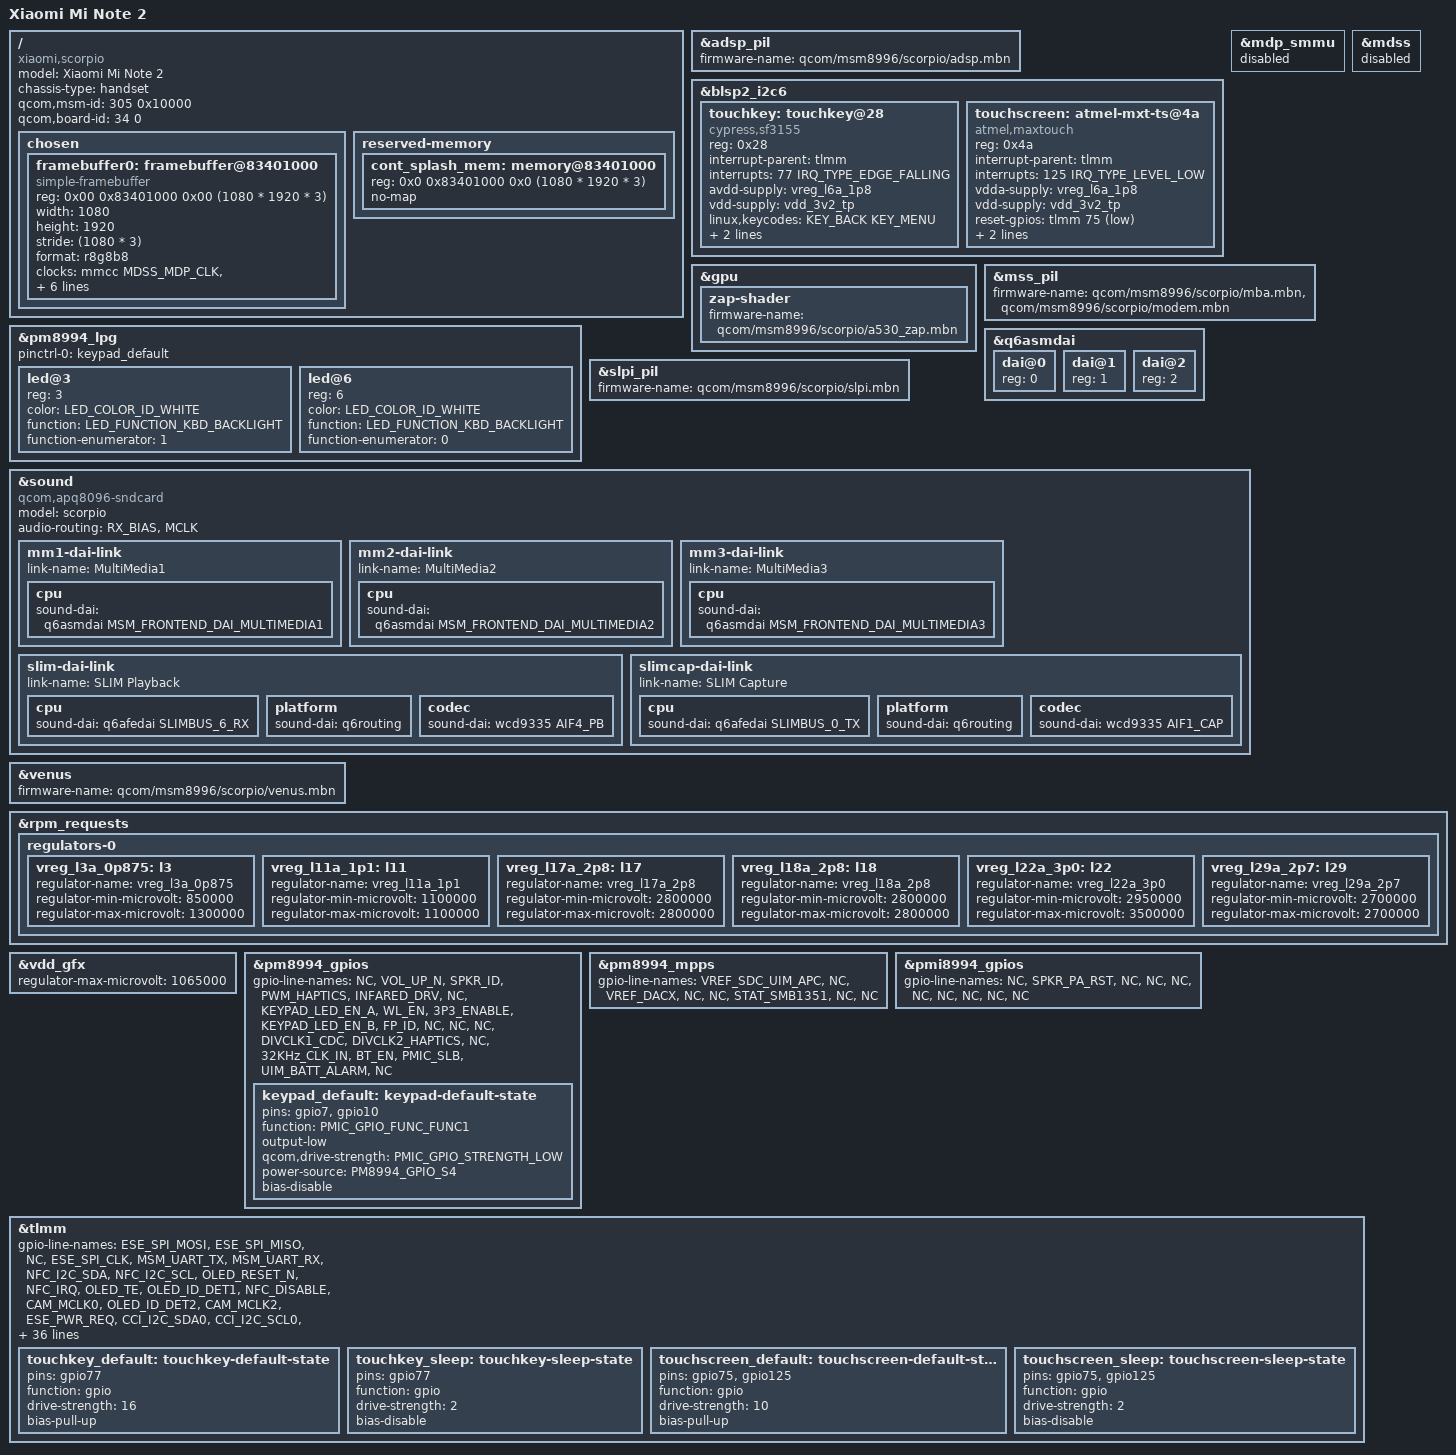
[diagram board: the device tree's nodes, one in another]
/dts-v1/;
#include "msm8996pro.dtsi"
#include "msm8996-xiaomi-common.dtsi"
#include "pmi8996.dtsi"
#include <dt-bindings/sound/qcom,q6afe.h>
#include <dt-bindings/sound/qcom,q6asm.h>
#include <dt-bindings/sound/qcom,wcd9335.h>
/ {
	model = "Xiaomi Mi Note 2";
	compatible = "xiaomi,scorpio", "qcom,msm8996pro", "qcom,msm8996";
	chassis-type = "handset";
	qcom,msm-id = <305 0x10000>;
	qcom,board-id = <34 0>;
	chosen {
		#address-cells = <2>;
		#size-cells = <2>;
		ranges;
		framebuffer0: framebuffer@83401000 {
			compatible = "simple-framebuffer";
			reg = <0x00 0x83401000 0x00 (1080 * 1920 * 3)>;
			width = <1080>;
			height = <1920>;
			stride = <(1080 * 3)>;
			format = "r8g8b8";
			clocks = <&mmcc MDSS_MDP_CLK>,
				 <&mmcc MMSS_MMAGIC_AHB_CLK>,
				 <&mmcc MDSS_AHB_CLK>,
				 <&mmcc MDSS_AXI_CLK>,
				 <&mmcc MMSS_MISC_AHB_CLK>,
				 <&mmcc MDSS_BYTE0_CLK>,
				 <&mmcc MDSS_PCLK0_CLK>,
				 <&mmcc MDSS_ESC0_CLK>,
				 <&mmcc SMMU_MDP_AHB_CLK>,
				 <&mmcc SMMU_MDP_AXI_CLK>;
			power-domains = <&mmcc MDSS_GDSC>;
		};
	};
	reserved-memory {
		cont_splash_mem: memory@83401000 {
			reg = <0x0 0x83401000 0x0 (1080 * 1920 * 3)>;
			no-map;
		};
	};
};
&adsp_pil {
	firmware-name = "qcom/msm8996/scorpio/adsp.mbn";
};
&blsp2_i2c6 {
	touchkey: touchkey@28 {
		compatible = "cypress,sf3155";
		reg = <0x28>;
		interrupt-parent = <&tlmm>;
		interrupts = <77 IRQ_TYPE_EDGE_FALLING>;
		avdd-supply = <&vreg_l6a_1p8>;
		vdd-supply = <&vdd_3v2_tp>;
		linux,keycodes = <KEY_BACK KEY_MENU>;
		pinctrl-names = "default", "sleep";
		pinctrl-0 = <&touchkey_default>;
		pinctrl-1 = <&touchkey_sleep>;
	};
	touchscreen: atmel-mxt-ts@4a {
		compatible = "atmel,maxtouch";
		reg = <0x4a>;
		interrupt-parent = <&tlmm>;
		interrupts = <125 IRQ_TYPE_LEVEL_LOW>;
		vdda-supply = <&vreg_l6a_1p8>;
		vdd-supply = <&vdd_3v2_tp>;
		reset-gpios = <&tlmm 75 GPIO_ACTIVE_LOW>;
		pinctrl-names = "default", "sleep";
		pinctrl-0 = <&touchscreen_default>;
		pinctrl-1 = <&touchscreen_sleep>;
	};
};
&gpu {
	zap-shader {
		firmware-name = "qcom/msm8996/scorpio/a530_zap.mbn";
	};
};
&mdp_smmu {
	status = "disabled";
};
&mdss {
	status = "disabled";
};
&mss_pil {
	firmware-name = "qcom/msm8996/scorpio/mba.mbn",
			"qcom/msm8996/scorpio/modem.mbn";
};
&pm8994_lpg {
	pinctrl-names = "default";
	pinctrl-0 = <&keypad_default>;
	led@3 {
		reg = <3>;
		color = <LED_COLOR_ID_WHITE>;
		function = LED_FUNCTION_KBD_BACKLIGHT;
		function-enumerator = <1>;
	};
	led@6 {
		reg = <6>;
		color = <LED_COLOR_ID_WHITE>;
		function = LED_FUNCTION_KBD_BACKLIGHT;
		function-enumerator = <0>;
	};
};
&q6asmdai {
	dai@0 {
		reg = <0>;
	};
	dai@1 {
		reg = <1>;
	};
	dai@2 {
		reg = <2>;
	};
};
&slpi_pil {
	firmware-name = "qcom/msm8996/scorpio/slpi.mbn";
};
&sound {
	compatible = "qcom,apq8096-sndcard";
	model = "scorpio";
	audio-routing = "RX_BIAS", "MCLK";
	mm1-dai-link {
		link-name = "MultiMedia1";
		cpu {
			sound-dai = <&q6asmdai MSM_FRONTEND_DAI_MULTIMEDIA1>;
		};
	};
	mm2-dai-link {
		link-name = "MultiMedia2";
		cpu {
			sound-dai = <&q6asmdai MSM_FRONTEND_DAI_MULTIMEDIA2>;
		};
	};
	mm3-dai-link {
		link-name = "MultiMedia3";
		cpu {
			sound-dai = <&q6asmdai MSM_FRONTEND_DAI_MULTIMEDIA3>;
		};
	};
	slim-dai-link {
		link-name = "SLIM Playback";
		cpu {
			sound-dai = <&q6afedai SLIMBUS_6_RX>;
		};
		platform {
			sound-dai = <&q6routing>;
		};
		codec {
			sound-dai = <&wcd9335 AIF4_PB>;
		};
	};
	slimcap-dai-link {
		link-name = "SLIM Capture";
		cpu {
			sound-dai = <&q6afedai SLIMBUS_0_TX>;
		};
		platform {
			sound-dai = <&q6routing>;
		};
		codec {
			sound-dai = <&wcd9335 AIF1_CAP>;
		};
	};
};
&venus {
	firmware-name = "qcom/msm8996/scorpio/venus.mbn";
};
&rpm_requests {
	regulators-0 {
		vreg_l3a_0p875: l3 {
			regulator-name = "vreg_l3a_0p875";
			regulator-min-microvolt = <850000>;
			regulator-max-microvolt = <1300000>;
		};
		vreg_l11a_1p1: l11 {
			regulator-name = "vreg_l11a_1p1";
			regulator-min-microvolt = <1100000>;
			regulator-max-microvolt = <1100000>;
		};
		vreg_l17a_2p8: l17 {
			regulator-name = "vreg_l17a_2p8";
			regulator-min-microvolt = <2800000>;
			regulator-max-microvolt = <2800000>;
		};
		vreg_l18a_2p8: l18 {
			regulator-name = "vreg_l18a_2p8";
			regulator-min-microvolt = <2800000>;
			regulator-max-microvolt = <2800000>;
		};
		vreg_l22a_3p0: l22 {
			regulator-name = "vreg_l22a_3p0";
			regulator-min-microvolt = <2950000>;
			regulator-max-microvolt = <3500000>;
		};
		vreg_l29a_2p7: l29 {
			regulator-name = "vreg_l29a_2p7";
			regulator-min-microvolt = <2700000>;
			regulator-max-microvolt = <2700000>;
		};
	};
};
&vdd_gfx {
	regulator-max-microvolt = <1065000>;
};
&pm8994_gpios {
	gpio-line-names =
		"NC",			 
		"VOL_UP_N",		 
		"SPKR_ID",		 
		"PWM_HAPTICS",		 
		"INFARED_DRV",		 
		"NC",			 
		"KEYPAD_LED_EN_A",	 
		"WL_EN",		 
		"3P3_ENABLE",		 
		"KEYPAD_LED_EN_B",	 
		"FP_ID",		 
		"NC",			 
		"NC",			 
		"NC",			 
		"DIVCLK1_CDC",		 
		"DIVCLK2_HAPTICS",	 
		"NC",			 
		"32KHz_CLK_IN",		 
		"BT_EN",		 
		"PMIC_SLB",		 
		"UIM_BATT_ALARM",	 
		"NC";			 
	keypad_default: keypad-default-state {
		pins = "gpio7", "gpio10";
		function = PMIC_GPIO_FUNC_FUNC1;
		output-low;
		qcom,drive-strength = <PMIC_GPIO_STRENGTH_LOW>;
		power-source = <PM8994_GPIO_S4>;
		bias-disable;
	};
};
&pm8994_mpps {
	gpio-line-names =
		"VREF_SDC_UIM_APC",	 
		"NC",			 
		"VREF_DACX",		 
		"NC",			 
		"NC",			 
		"STAT_SMB1351",		 
		"NC",			 
		"NC";			 
};
&pmi8994_gpios {
	gpio-line-names =
		"NC",			 
		"SPKR_PA_RST",		 
		"NC",			 
		"NC",			 
		"NC",			 
		"NC",			 
		"NC",			 
		"NC",			 
		"NC",			 
		"NC";			 
};
&tlmm {
	gpio-line-names =
		"ESE_SPI_MOSI",		 
		"ESE_SPI_MISO",		 
		"NC",			 
		"ESE_SPI_CLK",		 
		"MSM_UART_TX",		 
		"MSM_UART_RX",		 
		"NFC_I2C_SDA",		 
		"NFC_I2C_SCL",		 
		"OLED_RESET_N",		 
		"NFC_IRQ",		 
		"OLED_TE",		 
		"OLED_ID_DET1",		 
		"NFC_DISABLE",		 
		"CAM_MCLK0",		 
		"OLED_ID_DET2",		 
		"CAM_MCLK2",		 
		"ESE_PWR_REQ",		 
		"CCI_I2C_SDA0",		 
		"CCI_I2C_SCL0",		 
		"CCI_I2C_SDA1",		 
		"CCI_I2C_SCL1",		 
		"NFC_DWL_REQ",		 
		"CCI_TIMER1",		 
		"WEBCAM1_RESET_N",	 
		"ESE_IRQ",		 
		"NC",			 
		"WEBCAM1_STANDBY",	 
		"NC",			 
		"NC",			 
		"OLED_ERR_FG",		 
		"CAM1_RST_N",		 
		"HIFI_SW_MUTE",		 
		"NC",			 
		"NC",			 
		"FP_DOME_SW",		 
		"PCI_E0_RST_N",		 
		"PCI_E0_CLKREQ_N",	 
		"PCI_E0_WAKE",		 
		"OV_PWDN",		 
		"NC",			 
		"VDDR_1P6_EN",		 
		"QCA_UART_TXD",		 
		"QCA_UART_RXD",		 
		"QCA_UART_CTS",		 
		"QCA_UART_RTS",		 
		"MAWC_UART_TX",		 
		"MAWC_UART_RX",		 
		"NC",			 
		"NC",			 
		"AUDIO_SWITCH_EN",	 
		"FP_SPI_RST",		 
		"TYPEC_I2C_SDA",	 
		"TYPEC_I2C_SCL",	 
		"CODEC_INT2_N",		 
		"CODEC_INT1_N",		 
		"APPS_I2C7_SDA",	 
		"APPS_I2C7_SCL",	 
		"FORCE_USB_BOOT",	 
		"SPKR_I2S_BCK",		 
		"SPKR_I2S_WS",		 
		"SPKR_I2S_DOUT",	 
		"SPKR_I2S_DIN",		 
		"ESE_RSTN",		 
		"TYPEC_INT",		 
		"CODEC_RESET_N",	 
		"PCM_CLK",		 
		"PCM_SYNC",		 
		"PCM_DIN",		 
		"PCM_DOUT",		 
		"CDC_44K1_CLK",		 
		"SLIMBUS_CLK",		 
		"SLIMBUS_DATA0",	 
		"SLIMBUS_DATA1",	 
		"LDO_5V_IN_EN",		 
		"NC",			 
		"TSP_RST_N",		 
		"NC",			 
		"TOUCHKEY_INT",		 
		"SPKR_I2S_MCLK",	 
		"SPKR_PA_INT",		 
		"SENSOR_RESET_N",	 
		"FP_SPI_MOSI",		 
		"FP_SPI_MISO",		 
		"FP_SPI_CS_N",		 
		"FP_SPI_CLK",		 
		"HIFI_SD",		 
		"CAM_VDD_1P05_EN",	 
		"MSM_TS_I2C_SDA",	 
		"MSM_TS_I2C_SCL",	 
		"NC",			 
		"ESE_SPI_CS_N",		 
		"NC",			 
		"NC",			 
		"NC",			 
		"NC",			 
		"NC",			 
		"NC",			 
		"GRFC_0",		 
		"GRFC_1",		 
		"NC",			 
		"GRFC_3",		 
		"GRFC_4",		 
		"NC",			 
		"NC",			 
		"GRFC_7",		 
		"UIM2_DATA",		 
		"UIM2_CLK",		 
		"UIM2_RESET",		 
		"UIM2_PRESENT",		 
		"UIM1_DATA",		 
		"UIM1_CLK",		 
		"UIM1_RESET",		 
		"UIM1_PRESENT",		 
		"UIM_BATT_ALARM",	 
		"GRFC_8",		 
		"GRFC_9",		 
		"TX_GTR_THRES",		 
		"ACC_INT",		 
		"GYRO_INT",		 
		"COMPASS_INT",		 
		"PROXIMITY_INT_N",	 
		"FP_IRQ",		 
		"TSP_TA",		 
		"HALL_INTR2",		 
		"HALL_INTR1",		 
		"TS_INT_N",		 
		"NC",			 
		"GRFC_11",		 
		"HIFI_PWR_EN",		 
		"EXT_GPS_LNA_EN",	 
		"NC",			 
		"NC",			 
		"NC",			 
		"GRFC_14",		 
		"GSM_TX2_PHASE_D",	 
		"HIFI_SW_SEL",		 
		"GRFC_15",		 
		"RFFE3_DATA",		 
		"RFFE3_CLK",		 
		"NC",			 
		"NC",			 
		"RFFE5_DATA",		 
		"RFFE5_CLK",		 
		"NC",			 
		"COEX_UART_TX",		 
		"COEX_UART_RX",		 
		"RFFE2_DATA",		 
		"RFFE2_CLK",		 
		"RFFE1_DATA",		 
		"RFFE1_CLK";		 
	touchkey_default: touchkey-default-state {
		pins = "gpio77";
		function = "gpio";
		drive-strength = <16>;
		bias-pull-up;
	};
	touchkey_sleep: touchkey-sleep-state {
		pins = "gpio77";
		function = "gpio";
		drive-strength = <2>;
		bias-disable;
	};
	touchscreen_default: touchscreen-default-state {
		pins = "gpio75", "gpio125";
		function = "gpio";
		drive-strength = <10>;
		bias-pull-up;
	};
	touchscreen_sleep: touchscreen-sleep-state {
		pins = "gpio75", "gpio125";
		function = "gpio";
		drive-strength = <2>;
		bias-disable;
	};
};
